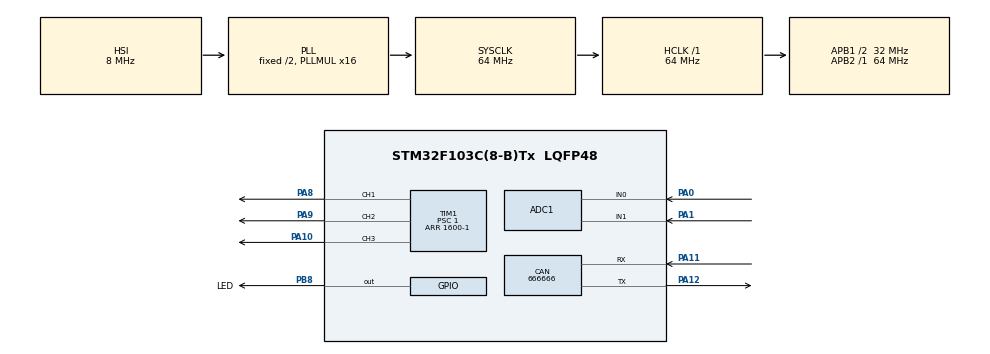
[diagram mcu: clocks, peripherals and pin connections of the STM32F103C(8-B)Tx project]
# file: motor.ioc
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ADC1.Channel-0\#ChannelInjectedConversion=ADC_CHANNEL_0
ADC1.Channel-1\#ChannelInjectedConversion=ADC_CHANNEL_1
ADC1.ContinuousConvMode=DISABLE
ADC1.EnableInjectedConversion=ENABLE
ADC1.EnableRegularConversion=DISABLE
ADC1.InjNumberOfConversion=2
ADC1.InjectedOffset-0\#ChannelInjectedConversion=0
ADC1.InjectedOffset-1\#ChannelInjectedConversion=0
ADC1.InjectedRank-0\#ChannelInjectedConversion=1
ADC1.InjectedRank-1\#ChannelInjectedConversion=2
ADC1.SamplingTime-0\#ChannelInjectedConversion=ADC_SAMPLETIME_1CYCLE_5
ADC1.SamplingTime-1\#ChannelInjectedConversion=ADC_SAMPLETIME_1CYCLE_5
ADC1.master=1
CAN.ABOM=ENABLE
CAN.CalculateBaudRate=666666
CAN.CalculateTimeBit=1500
CAN.CalculateTimeQuantum=500.0
Mcu.Family=STM32F1
Mcu.Name=STM32F103C(8-B)Tx
Mcu.Package=LQFP48
NVIC.ADC1_2_IRQn=true\:0\:0\:false\:false\:true\:true\:true\:true
NVIC.CAN1_RX1_IRQn=true\:0\:0\:false\:false\:true\:true\:true\:true
NVIC.PriorityGroup=NVIC_PRIORITYGROUP_4
NVIC.TIM1_CC_IRQn=true\:0\:0\:false\:false\:true\:true\:true\:true
NVIC.TIM2_IRQn=true\:1\:0\:true\:false\:true\:true\:true\:true
PA0-WKUP.Signal=ADCx_IN0
PA1.Signal=ADCx_IN1
PA10.Signal=S_TIM1_CH3
PA11.Mode=CAN_Activate
PA11.Signal=CAN_RX
PA12.Mode=CAN_Activate
PA12.Signal=CAN_TX
PA13.Mode=Serial_Wire
PA13.Signal=SYS_JTMS-SWDIO
PA14.Mode=Serial_Wire
PA14.Signal=SYS_JTCK-SWCLK
PA8.Signal=S_TIM1_CH1
PA9.Signal=S_TIM1_CH2
PB8.GPIO_Label=LED
PB8.GPIO_Speed=GPIO_SPEED_FREQ_MEDIUM
PB8.PinState=GPIO_PIN_SET
PB8.Signal=GPIO_Output
ProjectManager.HeapSize=0x200
ProjectManager.StackSize=0x400
ProjectManager.TargetToolchain=MDK-ARM V5.32
RCC.ADCPresc=RCC_ADCPCLK2_DIV6
RCC.AHBFreq_Value=64000000
RCC.APB1CLKDivider=RCC_HCLK_DIV2
RCC.APB1Freq_Value=32000000
RCC.APB1TimFreq_Value=64000000
RCC.APB2Freq_Value=64000000
RCC.APB2TimFreq_Value=64000000
RCC.HCLKFreq_Value=64000000
RCC.PLLMUL=RCC_PLL_MUL16
RCC.SYSCLKFreq_VALUE=64000000
RCC.SYSCLKSource=RCC_SYSCLKSOURCE_PLLCLK
RCC.USBFreq_Value=64000000
SH.ADCx_IN0.0=ADC1_IN0,IN0
SH.ADCx_IN1.0=ADC1_IN1,IN1
SH.S_TIM1_CH1.0=TIM1_CH1,PWM Generation1 CH1
SH.S_TIM1_CH2.0=TIM1_CH2,PWM Generation2 CH2
SH.S_TIM1_CH3.0=TIM1_CH3,PWM Generation3 CH3
TIM1.AutoReloadPreload=TIM_AUTORELOAD_PRELOAD_ENABLE
TIM1.Channel-Output\ Compare4\ No\ Output=TIM_CHANNEL_4
TIM1.Channel-PWM\ Generation1\ CH1=TIM_CHANNEL_1
TIM1.Channel-PWM\ Generation2\ CH2=TIM_CHANNEL_2
TIM1.Channel-PWM\ Generation3\ CH3=TIM_CHANNEL_3
TIM1.CounterMode=TIM_COUNTERMODE_CENTERALIGNED1
TIM1.OCMode_4=TIM_OCMODE_TIMING
TIM1.Period=1600-1
TIM1.Prescaler=1
TIM1.Pulse-Output\ Compare4\ No\ Output=350-1
TIM1.TIM_MasterOutputTrigger=TIM_TRGO_RESET
TIM1.TIM_MasterSlaveMode=TIM_MASTERSLAVEMODE_DISABLE
TIM2.Period=100
TIM2.Prescaler=640
VP_TIM1_VS_ClockSourceINT.Mode=Internal
VP_TIM1_VS_no_output4.Mode=Output Compare4 No Output
VP_TIM2_VS_ClockSourceINT.Mode=Internal
board=custom

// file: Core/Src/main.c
/* USER CODE BEGIN Header */
/**
  ******************************************************************************
  * @file           : main.c
  * @brief          : Main program body
  ******************************************************************************
  * @attention
  *
  * Copyright (c) 2025 STMicroelectronics.
  * All rights reserved.
  *
  * This software is licensed under terms that can be found in the LICENSE file
  * in the root directory of this software component.
  * If no LICENSE file comes with this software, it is provided AS-IS.
  *
  ******************************************************************************
  */
/* USER CODE END Header */
#include "main.h"
#include "adc.h"
#include "can.h"
#include "tim.h"
#include "gpio.h"

/* USER CODE BEGIN Includes */
#include "log.h"
#include "soft_iic.h"
#include "as5600.h"
#include "foc_init.h"
/* USER CODE END Includes */

void SystemClock_Config(void);

/* USER CODE BEGIN 0 */
uint16_t rawAngle;
uint16_t ccr;
/* USER CODE END 0 */

int main(void)
{

  /* MCU Configuration--------------------------------------------------------*/

  /* Reset of all peripherals, Initializes the Flash interface and the Systick. */
  HAL_Init();

  /* Configure the system clock */
  SystemClock_Config();

  /* Initialize all configured peripherals */
  MX_GPIO_Init();
  MX_TIM1_Init();
  MX_ADC1_Init();
  MX_TIM2_Init();
  MX_CAN_Init();
  /* USER CODE BEGIN 2 */
  log_init();
  I2C_Init();
  as5600Init();
  foc_root_init();

  foc_set_target(0,-(1<<14),0);

  /* USER CODE END 2 */
//    CAN_TxHeaderTypeDef TxHeader;
//    uint8_t TxData[8] = {0x01, 0x02, 0x03, 0x04, 0x05, 0x06, 0x07, 0x08}; // 发送的数据
//    uint32_t TxMailbox; // 用于返回使用的发送邮箱
//
//    // 配置发送报文头
//    TxHeader.StdId = 0x123;       // 标准标识符
//    TxHeader.ExtId = 0x00;        // 扩展标识符 (标准帧时通常为0)
//    TxHeader.IDE = CAN_ID_STD;    // 使用标准帧
//    TxHeader.RTR = CAN_RTR_DATA;  // 数据帧
//    TxHeader.DLC = 8;             // 数据长度 (0-8字节)
  /* Infinite loop */
  /* USER CODE BEGIN WHILE */
  while (1)
  {
//    HAL_ADCEx_InjectedStart_IT(&hadc1);
    // 等待有空闲的发送邮箱，然后发送
//    while(HAL_CAN_GetTxMailboxesFreeLevel(&hcan) == 0); // 等待空闲邮箱
//    if (HAL_CAN_AddTxMessage(&hcan, &TxHeader, TxData, &TxMailbox) != HAL_OK)
//    {
//        // 发送错误处理
//        Error_Handler();
//    }

//      if(ccr == 1600)
//          ccr = 0;
//      else
//          ccr++;
//
//    __HAL_TIM_SET_COMPARE(&htim1, TIM_CHANNEL_1, ccr);
//    __HAL_TIM_SET_COMPARE(&htim1, TIM_CHANNEL_2, 0);
//    __HAL_TIM_SET_COMPARE(&htim1, TIM_CHANNEL_3, 0);
//
    HAL_Delay(1);

//      __HAL_TIM_SET_COMPARE(&htim1, TIM_CHANNEL_4, ccr);
//    HAL_GPIO_TogglePin(LED_GPIO_Port,LED_Pin);
//    HAL_Delay(500);
//    rawAngle = foc_get_angle();
//    printf("%d\r\n",rawAngle);
    /* USER CODE END WHILE */

  }
}

void SystemClock_Config(void)
{
  RCC_OscInitTypeDef RCC_OscInitStruct = {0};
  RCC_ClkInitTypeDef RCC_ClkInitStruct = {0};
  RCC_PeriphCLKInitTypeDef PeriphClkInit = {0};

  /** Initializes the RCC Oscillators according to the specified parameters
  * in the RCC_OscInitTypeDef structure.
  */
  RCC_OscInitStruct.OscillatorType = RCC_OSCILLATORTYPE_HSI;
  RCC_OscInitStruct.HSIState = RCC_HSI_ON;
  RCC_OscInitStruct.HSICalibrationValue = RCC_HSICALIBRATION_DEFAULT;
  RCC_OscInitStruct.PLL.PLLState = RCC_PLL_ON;
  RCC_OscInitStruct.PLL.PLLSource = RCC_PLLSOURCE_HSI_DIV2;
  RCC_OscInitStruct.PLL.PLLMUL = RCC_PLL_MUL16;
  if (HAL_RCC_OscConfig(&RCC_OscInitStruct) != HAL_OK)
  {
    Error_Handler();
  }

  /** Initializes the CPU, AHB and APB buses clocks
  */
  RCC_ClkInitStruct.ClockType = RCC_CLOCKTYPE_HCLK|RCC_CLOCKTYPE_SYSCLK
                              |RCC_CLOCKTYPE_PCLK1|RCC_CLOCKTYPE_PCLK2;
  RCC_ClkInitStruct.SYSCLKSource = RCC_SYSCLKSOURCE_PLLCLK;
  RCC_ClkInitStruct.AHBCLKDivider = RCC_SYSCLK_DIV1;
  RCC_ClkInitStruct.APB1CLKDivider = RCC_HCLK_DIV2;
  RCC_ClkInitStruct.APB2CLKDivider = RCC_HCLK_DIV1;

  if (HAL_RCC_ClockConfig(&RCC_ClkInitStruct, FLASH_LATENCY_2) != HAL_OK)
  {
    Error_Handler();
  }
  PeriphClkInit.PeriphClockSelection = RCC_PERIPHCLK_ADC;
  PeriphClkInit.AdcClockSelection = RCC_ADCPCLK2_DIV6;
  if (HAL_RCCEx_PeriphCLKConfig(&PeriphClkInit) != HAL_OK)
  {
    Error_Handler();
  }
}

void Error_Handler(void)
{
  /* USER CODE BEGIN Error_Handler_Debug */
  /* User can add his own implementation to report the HAL error return state */
  __disable_irq();
  while (1)
  {
      printf("Error Handler");
  }
  /* USER CODE END Error_Handler_Debug */
}
